# LargeDummyDevice register map
File version: 1.0
Registers are 32-bit, read-write, no defined reset value unless marked. A register's access mark holds for its fields unless they carry their own. Offsets are from the block's base; [hi:lo] are bit positions.

## PERIPHERAL_79
Base 0x4004E000
0x04 REG_1 — Register 1
  [30] FIELD_17, [29:28] FIELD_2, [27] FIELD_3, [26] FIELD_10, [26:25] FIELD_24, [23] FIELD_18, [22] FIELD_23, [22:21] FIELD_13, [24:20] FIELD_7, [17] FIELD_11, [17:16] FIELD_12, [15] FIELD_5, [16:15] FIELD_21, [13] FIELD_9, [16:12] FIELD_14, [12:10] FIELD_19, [13:9] FIELD_15, [12:8] FIELD_1, [8:7] FIELD_6, [6:5] FIELD_4, [6:4] FIELD_22, [5:2] FIELD_8, [3:2] FIELD_16, [0] FIELD_20
0x08 REG_2 — Register 2
  [32:31] FIELD_11, [32:30] FIELD_3, [32:30] FIELD_16, [31:28] FIELD_6, [29:28] FIELD_27, [27] FIELD_1, [27:25] FIELD_10, [27:25] FIELD_13, [25] FIELD_14, [27:24] FIELD_21, [26:23] FIELD_18, [19] FIELD_23, [22:18] FIELD_25, [19:16] FIELD_9, [17:14] FIELD_4, [17:14] FIELD_8, [18:14] FIELD_17, [15:11] FIELD_20, [11:9] FIELD_19, [12:9] FIELD_26, [10:8] FIELD_7, [7:5] FIELD_15, [5:2] FIELD_24, [2:1] FIELD_2, [1] FIELD_12, [1] FIELD_22, [1:0] FIELD_5
0x0C REG_3 — Register 3
  [31] FIELD_4, [33:30] FIELD_25, [31:29] FIELD_1, [29] FIELD_11, [29:26] FIELD_26, [26:25] FIELD_5, [24] FIELD_14, [22:21] FIELD_17, [18] FIELD_24, [17:15] FIELD_15, [18:14] FIELD_19, [11] FIELD_23, [8] FIELD_3, [9:8] FIELD_9, [8] FIELD_20, [9:7] FIELD_2, [11:7] FIELD_8, [9:6] FIELD_7, [7:4] FIELD_18, [7:3] FIELD_6, [6:2] FIELD_10, [6:2] FIELD_12, [3:2] FIELD_13, [3:1] FIELD_16, [2:1] FIELD_21, [0] FIELD_22
0x10 REG_4 — Register 4
  [33:30] FIELD_2, [33:29] FIELD_5, [31:29] FIELD_10, [31:28] FIELD_6, [30:26] FIELD_11, [20] FIELD_3, [12:11] FIELD_1, [10] FIELD_8, [10:8] FIELD_9, [4:2] FIELD_4, [1:0] FIELD_7
0x14 REG_5 — Register 5
  [32:31] FIELD_8, [30:26] FIELD_2, [24:20] FIELD_1, [16:15] FIELD_5, [17:15] FIELD_7, [18:14] FIELD_6, [12:11] FIELD_3, [14:11] FIELD_4, [11:9] FIELD_10, [8:4] FIELD_9
0x18 REG_6 — Register 6
  [29] FIELD_8, [28] FIELD_4, [27:26] FIELD_1, [27:26] FIELD_3, [25] FIELD_5, [17:15] FIELD_11, [17:14] FIELD_7, [16:12] FIELD_2, [15:11] FIELD_6, [11:8] FIELD_10, [2] FIELD_9
0x1C REG_7 — Register 7
  [35:31] FIELD_18, [32:31] FIELD_21, [33:29] FIELD_20, [29:28] FIELD_7, [28:25] FIELD_4, [24] FIELD_16, [25:22] FIELD_17, [21:19] FIELD_3, [21:18] FIELD_22, [19:15] FIELD_5, [15:14] FIELD_9, [15:12] FIELD_1, [11:10] FIELD_10, [11:7] FIELD_2, [5] FIELD_13, [4:3] FIELD_15, [6:2] FIELD_19, [2:1] FIELD_8, [5:1] FIELD_11, [1] FIELD_14, [2:0] FIELD_6, [0] FIELD_12
0x20 REG_8 — Register 8
  [28] FIELD_4, [25] FIELD_6, [27:24] FIELD_12, [27:23] FIELD_8, [22] FIELD_3, [23:20] FIELD_2, [21:18] FIELD_10, [12] FIELD_1, [6] FIELD_9, [6:5] FIELD_11, [5:3] FIELD_5, [5:3] FIELD_7
0x24 REG_9 — Register 9
  [33:30] FIELD_8, [31:29] FIELD_10, [29:27] FIELD_13, [25:24] FIELD_11, [24] FIELD_20, [19] FIELD_12, [22:19] FIELD_18, [19:18] FIELD_14, [22:18] FIELD_19, [15:14] FIELD_6, [14] FIELD_17, [14:12] FIELD_15, [14:10] FIELD_3, [11:10] FIELD_4, [10:7] FIELD_9, [8:7] FIELD_16, [6] FIELD_7, [8:5] FIELD_5, [8:4] FIELD_1, [2:1] FIELD_2
0x28 REG_10 — Register 10
  [32:29] FIELD_4, [27] FIELD_2, [12:9] FIELD_1, [9] FIELD_5, [9:8] FIELD_3
0x2C REG_11 — Register 11
  [17:14] FIELD_2, [16:14] FIELD_5, [13:12] FIELD_4, [6] FIELD_3, [1] FIELD_1, [0] FIELD_6
0x30 REG_12 — Register 12
  [27:23] FIELD_12, [22:18] FIELD_8, [18:14] FIELD_1, [15:11] FIELD_9, [14:10] FIELD_4, [10] FIELD_7, [13:9] FIELD_5, [13:9] FIELD_10, [11:7] FIELD_2, [10:7] FIELD_3, [3:2] FIELD_6, [2:1] FIELD_11
0x34 REG_13 — Register 13
  [34:31] FIELD_24, [29] FIELD_12, [28:27] FIELD_9, [31:27] FIELD_21, [31:27] FIELD_27, [27:26] FIELD_6, [27:26] FIELD_31, [27:25] FIELD_1, [28:24] FIELD_17, [28:24] FIELD_19, [24] FIELD_20, [25:23] FIELD_2, [26:23] FIELD_8, [20] FIELD_10, [21:20] FIELD_30, [19] FIELD_13, [19:16] FIELD_4, [20:16] FIELD_29, [14:11] FIELD_11, [15:11] FIELD_15, [13:10] FIELD_23, [8] FIELD_3, [7] FIELD_18, [8:7] FIELD_22, [6:5] FIELD_26, [3] FIELD_14, [5:3] FIELD_25, [3:2] FIELD_5, [4:1] FIELD_7, [0] FIELD_16, [2:0] FIELD_28
0x38 REG_14 — Register 14
  [31:30] FIELD_6, [31:28] FIELD_15, [28] FIELD_32, [31:27] FIELD_5, [29:26] FIELD_19, [29:26] FIELD_26, [29:25] FIELD_12, [26:25] FIELD_28, [24:23] FIELD_3, [25:23] FIELD_22, [23:22] FIELD_2, [22] FIELD_8, [23:20] FIELD_16, [22:20] FIELD_21, [23:19] FIELD_18, [19:18] FIELD_7, [19:16] FIELD_13, [18:15] FIELD_20, [19:15] FIELD_24, [14:12] FIELD_9, [14:11] FIELD_25, [11:9] FIELD_11, [11:7] FIELD_4, [8:7] FIELD_29, [7:6] FIELD_1, [7:6] FIELD_14, [8:6] FIELD_31, [9:5] FIELD_30, [5:4] FIELD_10, [8:4] FIELD_23, [2] FIELD_17, [5:2] FIELD_27
0x3C REG_15 — Register 15
  [32:30] FIELD_27, [26] FIELD_15, [27:26] FIELD_24, [25] FIELD_8, [24] FIELD_1, [22:20] FIELD_13, [20:18] FIELD_14, [19:18] FIELD_16, [20:18] FIELD_18, [18:16] FIELD_11, [15] FIELD_2, [17:15] FIELD_17, [16:14] FIELD_5, [17:13] FIELD_7, [15:13] FIELD_12, [11] FIELD_19, [11:10] FIELD_21, [8] FIELD_10, [7:6] FIELD_28, [7:5] FIELD_9, [7:5] FIELD_25, [6:4] FIELD_23, [5:3] FIELD_20, [4:2] FIELD_4, [4:2] FIELD_26, [5:1] FIELD_3, [2:1] FIELD_6, [0] FIELD_22
0x40 REG_16 — Register 16
  [32:31] FIELD_13, [30:28] FIELD_9, [29:27] FIELD_10, [31:27] FIELD_16, [29:25] FIELD_6, [26:22] FIELD_1, [23:21] FIELD_8, [23:21] FIELD_14, [23:21] FIELD_15, [21:18] FIELD_2, [19:15] FIELD_5, [10:9] FIELD_17, [9:8] FIELD_4, [7:6] FIELD_3, [8:5] FIELD_11, [3:2] FIELD_12, [2:0] FIELD_7
0x44 REG_17 — Register 17
  [34:31] FIELD_16, [33:30] FIELD_13, [27:25] FIELD_14, [25:22] FIELD_7, [22] FIELD_8, [21] FIELD_5, [24:20] FIELD_11, [18:17] FIELD_4, [16:12] FIELD_2, [12] FIELD_15, [13:11] FIELD_3, [14:11] FIELD_10, [10:8] FIELD_9, [10:7] FIELD_1, [9:5] FIELD_17, [4] FIELD_12, [5:1] FIELD_6
0x48 REG_18 — Register 18
  [32:31] FIELD_9, [32:30] FIELD_4, [31:29] FIELD_5, [30:28] FIELD_12, [29:25] FIELD_13, [22:20] FIELD_1, [20:19] FIELD_7, [19:16] FIELD_8, [16:15] FIELD_14, [17:13] FIELD_3, [14:12] FIELD_10, [12] FIELD_11, [10:9] FIELD_2, [11:8] FIELD_6
0x4C REG_19 — Register 19
  [32:30] FIELD_14, [30:26] FIELD_7, [23] FIELD_15, [27:23] FIELD_18, [26:22] FIELD_16, [22:21] FIELD_11, [24:20] FIELD_8, [21:19] FIELD_4, [19] FIELD_12, [22:19] FIELD_21, [20:18] FIELD_1, [16:14] FIELD_3, [18:14] FIELD_13, [16:14] FIELD_20, [11] FIELD_22, [9:6] FIELD_2, [6:5] FIELD_5, [4] FIELD_17, [5:4] FIELD_19, [4:2] FIELD_9, [1] FIELD_6, [5:1] FIELD_10
0x50 REG_20 — Register 20
  [33:30] FIELD_14, [33:29] FIELD_4, [32:28] FIELD_10, [26:25] FIELD_1, [25:24] FIELD_8, [26:23] FIELD_12, [21] FIELD_11, [23:20] FIELD_15, [19:15] FIELD_7, [17:14] FIELD_2, [18:14] FIELD_13, [15:14] FIELD_17, [13:12] FIELD_16, [11:9] FIELD_3, [12:9] FIELD_5, [1] FIELD_9, [4:0] FIELD_6
0x54 REG_21 — Register 21
  [31:29] FIELD_2, [28:27] FIELD_17, [28:26] FIELD_11, [25:22] FIELD_1, [25:22] FIELD_16, [23:21] FIELD_18, [21:18] FIELD_21, [18:16] FIELD_23, [15] FIELD_4, [13] FIELD_24, [11] FIELD_10, [10] FIELD_5, [11:10] FIELD_20, [8] FIELD_15, [8:7] FIELD_6, [11:7] FIELD_9, [9:7] FIELD_12, [8:6] FIELD_3, [8:4] FIELD_22, [3:1] FIELD_7, [2:0] FIELD_8, [3:0] FIELD_13, [1:0] FIELD_14, [3:0] FIELD_19
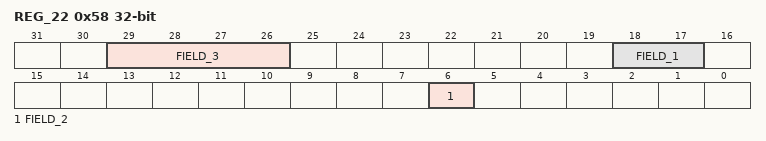
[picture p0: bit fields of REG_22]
0x58 REG_22 — Register 22
  [29:26] FIELD_3, [18:17] FIELD_1, [6] FIELD_2
0x5C REG_23 — Register 23
  [32:29] FIELD_12, [32:28] FIELD_20, [31:27] FIELD_18, [30:26] FIELD_3, [28:25] FIELD_13, [24:23] FIELD_14, [24:23] FIELD_19, [26:22] FIELD_8, [24:21] FIELD_6, [25:21] FIELD_9, [14:12] FIELD_15, [14:12] FIELD_21, [15:11] FIELD_17, [11:10] FIELD_5, [12:9] FIELD_7, [11:7] FIELD_4, [6] FIELD_22, [5:2] FIELD_10, [2] FIELD_11, [3:1] FIELD_2, [0] FIELD_1, [3:0] FIELD_16
